# CM_CORE__CORE register map
Vendor: Texas Instruments
Peripheral module from a debugger description file (folder am572x).
Registers are 32-bit, read-only, reset 0x30001 unless marked. A register's access mark holds for its fields unless they carry their own. Offsets are as the file gives them; lines under a group give offsets from that group; [hi:lo] are bit positions; {n}, {i} and the like mark numbered series; 'fields as' and 'values as' point back to an identical list; <NAME> marks a mode.

## CM_CORE__CORE
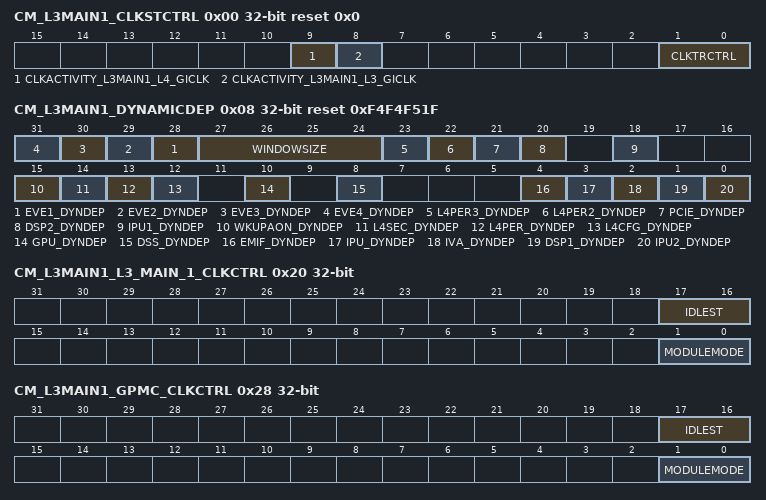
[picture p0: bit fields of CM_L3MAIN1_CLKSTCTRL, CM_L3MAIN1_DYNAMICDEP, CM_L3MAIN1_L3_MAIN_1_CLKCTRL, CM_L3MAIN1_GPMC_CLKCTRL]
0x00 CM_L3MAIN1_CLKSTCTRL access per field reset 0x0 — This register enables the domain power state transition. It controls the HW supervised domain power state transition between ON-ACTIVE and ON-INACTIVE states. It also hold one status bit per clock input of the domain.
  [9] CLKACTIVITY_L3MAIN1_L4_GICLK ro — This field indicates the state of the L3MAIN1_L4_GICLK clock in the domain. [warm reset insensitive]
    0=INACT (Corresponding clock is definitely gated); 1=ACT (Corresponding clock is running or gating/ungating transition is on-going)
  [8] CLKACTIVITY_L3MAIN1_L3_GICLK ro — This field indicates the state of the L3MAIN1_L3_GICLK clock in the domain. [warm reset insensitive]
    values as CLKACTIVITY_L3MAIN1_L4_GICLK
  [1:0] CLKTRCTRL rw — Controls the clock state transition of the L3MAIN1 clock domain.
    0=NO_SLEEP (NO_SLEEP: Sleep transition cannot be initiated. Wakeup transition may however occur.); 3=HW_AUTO (HW_AUTO: Automatic transition is enabled. Sleep and wakeup transition are based upon hardware conditions.)
0x08 CM_L3MAIN1_DYNAMICDEP access per field reset 0xF4F4F51F — This register controls the dynamic domain depedencies from L3MAIN1 domain towards 'target' domains. It is relevant only for domain having OCP master port(s).
  [n+27] EVE{n}_DYNDEP ro (n=1..4) — Dynamic dependency towards EVE{n} clock domain
    1=ENABLED (Dependency is enabled)
  [27:24] WINDOWSIZE rw — Size of sliding window used to monitor OCP interface activity for determination of auto-sleep feature. Time unit defined byCM_DYN_DEP_PRESCAL register.
  [23] L4PER3_DYNDEP ro — Dynamic dependency towards L4PER3 clock domain
    1=ENABLED (Dependency is enabled)
  [22] L4PER2_DYNDEP ro — Dynamic dependency towards L4PER2 clock domain
    1=ENABLED (Dependency is enabled)
  [21] PCIE_DYNDEP ro — Dynamic dependency towards PCIE clock domain
    1=ENABLED (Dependency is enabled)
  [20] DSP2_DYNDEP ro — Dynamic dependency towards DSP2 clock domain
    1=ENABLED (Dependency is enabled)
  [18] IPU1_DYNDEP ro — Dynamic dependency towards IPU1 clock domain
    1=ENABLED (Dependency is enabled)
  [15] WKUPAON_DYNDEP ro — Dynamic dependency towards WKUPAON clock domain
    1=ENABLED (Dependency is enabled)
  [14] L4SEC_DYNDEP ro — Dynamic dependency towards L4SEC clock domain
    1=ENABLED (Dependency is enabled)
  [13] L4PER_DYNDEP ro — Dynamic dependency towards L4PER1 clock domain
    1=ENABLED (Dependency is enabled)
  [12] L4CFG_DYNDEP ro — Dynamic dependency towards L4CFG clock domain
    1=ENABLED (Dependency is enabled)
  [10] GPU_DYNDEP ro — Dynamic dependency towards GPU clock domain
    1=ENABLED (Dependency is enabled)
  [8] DSS_DYNDEP ro — Dynamic dependency towards DSS clock domain
    1=ENABLED (Dependency is enabled)
  [4] EMIF_DYNDEP ro — Dynamic dependency towards EMIF clock domain
    1=ENABLED (Dependency is enabled)
  [3] IPU_DYNDEP ro — Dynamic dependency towards IPU clock domain
    1=ENABLED (Dependency is enabled)
  [2] IVA_DYNDEP ro — Dynamic dependency towards IVA clock domain
    1=ENABLED (Dependency is enabled)
  [1] DSP1_DYNDEP ro — Dynamic dependency towards DSP1 clock domain
    1=ENABLED (Dependency is enabled)
  [0] IPU2_DYNDEP ro — Dynamic dependency towards IPU2 clock domain
    1=ENABLED (Dependency is enabled)
0x20 CM_L3MAIN1_L3_MAIN_1_CLKCTRL — This register manages the L3_MAIN_1 clocks.
  [17:16] IDLEST — Module idle status. [warm reset insensitive]
    0=FUNC (Module is fully functional, including OCP); 1=TRANS (Module is performing transition: wakeup, or sleep, or sleep abortion); 2=IDLE (Module is in Idle mode (only OCP part). It is functional if using separate functional clock); 3=DISABLE (Module is disabled and cannot be accessed)
  [1:0] MODULEMODE — Control the way mandatory clocks are managed.
    1=AUTO (Module is managed automatically by HW according to clock domain transition. A clock domain sleep transition put module into idle. A wakeup domain transition put it back into function. If CLKTRCTRL=3, any OCP access to module is always granted. Module clocks may be gated according to the clock domain state.)
0x28 CM_L3MAIN1_GPMC_CLKCTRL access per field — This register manages the GPMC clocks.
  [17:16] IDLEST ro — Module idle status. [warm reset insensitive]
    values as CM_L3MAIN1_L3_MAIN_1_CLKCTRL.IDLEST
  [1:0] MODULEMODE rw — Control the way mandatory clocks are managed.
    0=DISABLED (Module is temporarily disabled by SW. OCP access to module are stalled. Can be used to change timing parameter of GPMC module.); 1=AUTO (Module is managed automatically by HW according to clock domain transition. A clock domain sleep transition put module into idle. A wakeup domain transition put it back into function. If CLKTRCTRL=3, any OCP access to module is always granted. Module clocks may be gated according to the clock domain state.)
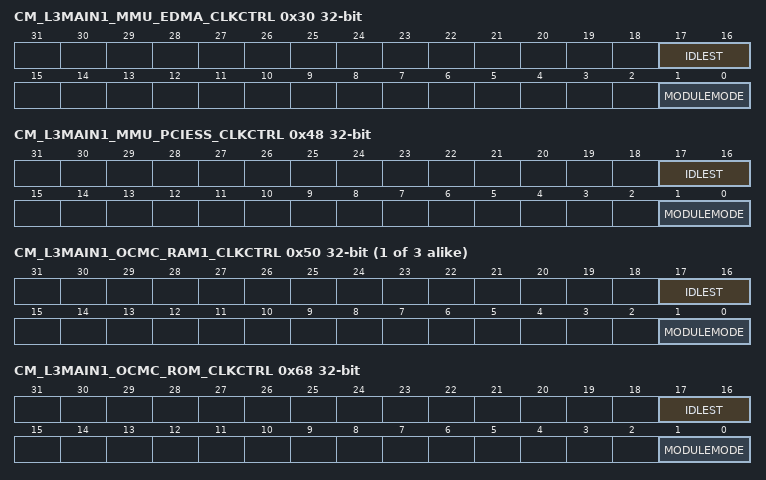
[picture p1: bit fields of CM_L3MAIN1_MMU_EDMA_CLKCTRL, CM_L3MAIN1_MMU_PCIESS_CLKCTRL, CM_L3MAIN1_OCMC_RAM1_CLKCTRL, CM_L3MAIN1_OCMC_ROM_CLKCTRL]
0x30 CM_L3MAIN1_MMU_EDMA_CLKCTRL — This register manages the MMU_L4_EDMA clocks.
  fields as CM_L3MAIN1_L3_MAIN_1_CLKCTRL
0x48 CM_L3MAIN1_MMU_PCIESS_CLKCTRL — This register manages the MMU_L4_PCIESS clocks.
  fields as CM_L3MAIN1_L3_MAIN_1_CLKCTRL
{0x48+8i} CM_L3MAIN1_OCMC_RAM{i}_CLKCTRL (i=1..3) — This register manages the OCMC_RAM{i} clocks.
  fields as CM_L3MAIN1_L3_MAIN_1_CLKCTRL
0x68 CM_L3MAIN1_OCMC_ROM_CLKCTRL — This register manages the OCMC_RAM clocks.
  fields as CM_L3MAIN1_L3_MAIN_1_CLKCTRL
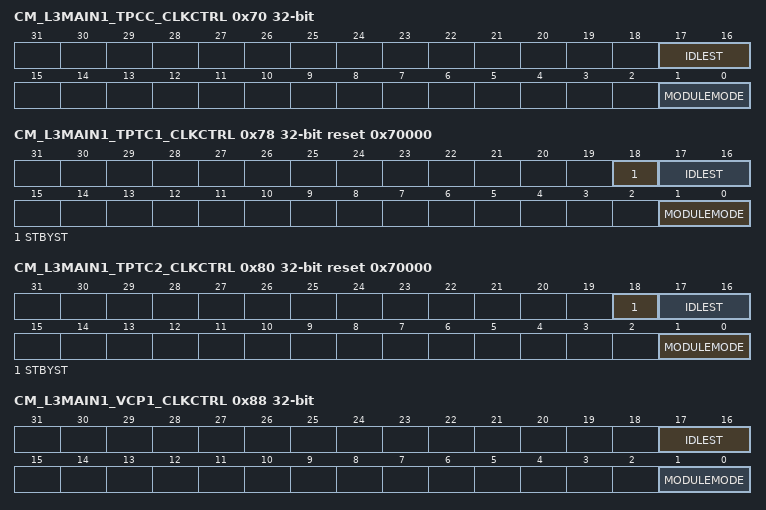
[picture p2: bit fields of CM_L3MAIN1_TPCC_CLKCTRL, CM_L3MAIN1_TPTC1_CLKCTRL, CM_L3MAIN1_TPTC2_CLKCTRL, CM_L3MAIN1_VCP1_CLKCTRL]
0x70 CM_L3MAIN1_TPCC_CLKCTRL — This register manages the TPCC clocks.
  fields as CM_L3MAIN1_L3_MAIN_1_CLKCTRL
0x78 CM_L3MAIN1_TPTC1_CLKCTRL access per field reset 0x70000 — This register manages the TPTC1 clocks.
  [18] STBYST ro — Module standby status. [warm reset insensitive]
    0=FUNC (Module is functional (not in standby)); 1=STANDBY (Module is in standby)
  [17:16] IDLEST ro — Module idle status. [warm reset insensitive]
    values as CM_L3MAIN1_L3_MAIN_1_CLKCTRL.IDLEST
  [1:0] MODULEMODE rw — Control the way mandatory clocks are managed.
    0=DISABLED (Module is disabled by SW. Any OCP access to module results in an error, except if resulting from a module wakeup (asynchronous wakeup).); 1=AUTO (Module is managed automatically by HW according to clock domain transition. A clock domain sleep transition put module into idle. A wakeup domain transition put it back into function. If CLKTRCTRL=3, any OCP access to module is always granted. Module clocks may be gated according to the clock domain state.)
0x80 CM_L3MAIN1_TPTC2_CLKCTRL access per field reset 0x70000 — This register manages the TPTC2 clocks.
  fields as CM_L3MAIN1_TPTC1_CLKCTRL
0x88 CM_L3MAIN1_VCP1_CLKCTRL — This register manages the VCP1 clocks.
  [17:16] IDLEST — Module idle status. [warm reset insensitive]
    0=FUNC (Module is fully functional, including OCP); 1=TRANS (Module is performing transition: wakeup, or sleep, or sleep abortion); 2=DISABLE (Module is in Idle mode (only OCP part). It is functional if using separate functional clock); 3=IDLE (Module is disabled and cannot be accessed)
  [1:0] MODULEMODE — Control the way mandatory clocks are managed.
    values as CM_L3MAIN1_L3_MAIN_1_CLKCTRL.MODULEMODE
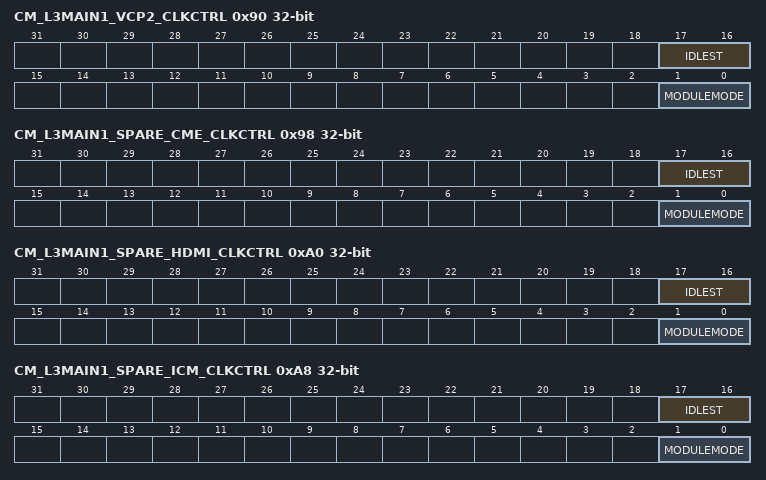
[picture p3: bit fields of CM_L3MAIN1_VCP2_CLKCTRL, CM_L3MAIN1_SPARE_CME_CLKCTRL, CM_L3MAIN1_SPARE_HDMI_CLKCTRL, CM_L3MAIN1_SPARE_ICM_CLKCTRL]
0x90 CM_L3MAIN1_VCP2_CLKCTRL — This register manages the VCP2 clocks.
  fields as CM_L3MAIN1_L3_MAIN_1_CLKCTRL
0x98 CM_L3MAIN1_SPARE_CME_CLKCTRL — This register manages the SPARE_CME clocks.
  fields as CM_L3MAIN1_L3_MAIN_1_CLKCTRL
0xA0 CM_L3MAIN1_SPARE_HDMI_CLKCTRL — This register manages the SPARE_HDMI clocks.
  fields as CM_L3MAIN1_L3_MAIN_1_CLKCTRL
0xA8 CM_L3MAIN1_SPARE_ICM_CLKCTRL — This register manages the SPARE_ICM clocks.
  fields as CM_L3MAIN1_L3_MAIN_1_CLKCTRL
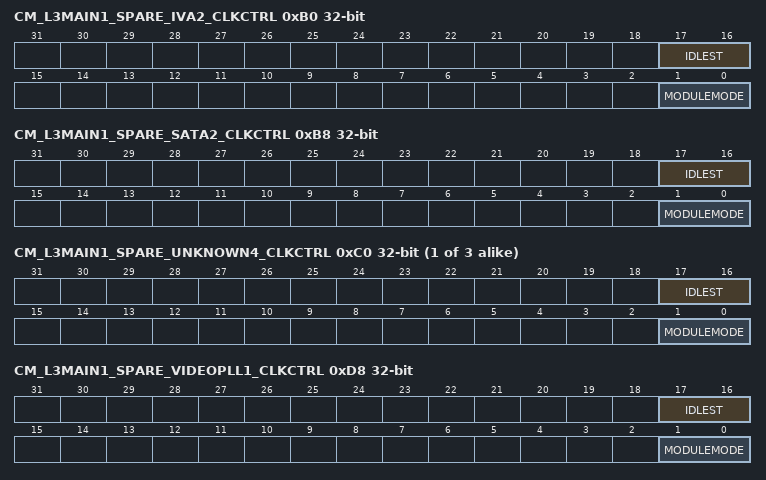
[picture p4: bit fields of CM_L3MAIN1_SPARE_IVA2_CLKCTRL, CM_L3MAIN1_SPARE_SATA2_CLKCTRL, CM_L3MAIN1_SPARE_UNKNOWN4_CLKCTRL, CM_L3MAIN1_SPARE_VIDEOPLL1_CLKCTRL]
0xB0 CM_L3MAIN1_SPARE_IVA2_CLKCTRL — This register manages the SPARE_IVA2 clocks.
  fields as CM_L3MAIN1_L3_MAIN_1_CLKCTRL
0xB8 CM_L3MAIN1_SPARE_SATA2_CLKCTRL — This register manages the SPARE_SATA2 clocks.
  fields as CM_L3MAIN1_L3_MAIN_1_CLKCTRL
{0xA0+8i} CM_L3MAIN1_SPARE_UNKNOWN{i}_CLKCTRL (i=4..6) — This register manages the SPARE_UNKNOWN{i} clocks.
  fields as CM_L3MAIN1_L3_MAIN_1_CLKCTRL
0xD8 CM_L3MAIN1_SPARE_VIDEOPLL1_CLKCTRL — This register manages the SPARE_VIDEOPLL1 clocks.
  fields as CM_L3MAIN1_L3_MAIN_1_CLKCTRL
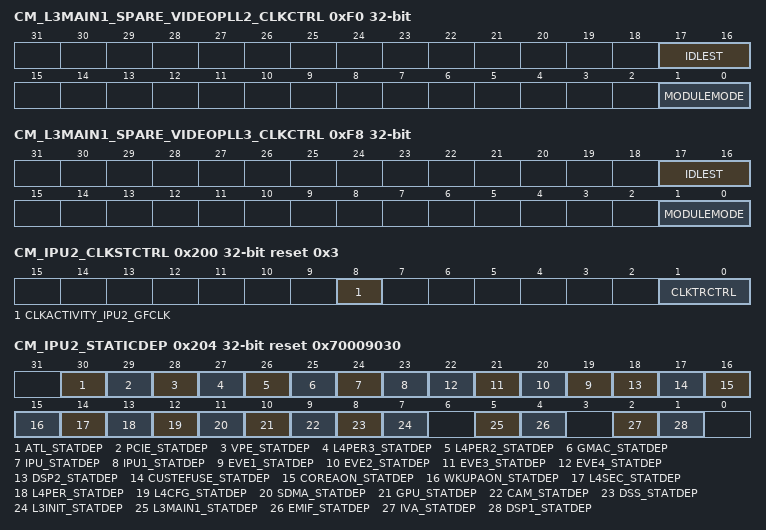
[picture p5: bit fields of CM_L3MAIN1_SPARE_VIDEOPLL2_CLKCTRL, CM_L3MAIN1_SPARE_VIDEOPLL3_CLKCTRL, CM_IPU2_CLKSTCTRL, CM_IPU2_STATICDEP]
0xF0 CM_L3MAIN1_SPARE_VIDEOPLL2_CLKCTRL — This register manages the SPARE_VIDEOPLL2 clocks.
  fields as CM_L3MAIN1_L3_MAIN_1_CLKCTRL
0xF8 CM_L3MAIN1_SPARE_VIDEOPLL3_CLKCTRL — This register manages the SPARE_VIDEOPLL3 clocks.
  fields as CM_L3MAIN1_L3_MAIN_1_CLKCTRL
0x200 CM_IPU2_CLKSTCTRL access per field reset 0x3 — This register enables the domain power state transition. It controls the HW supervised domain power state transition between ON-ACTIVE and ON-INACTIVE states. It also hold one status bit per clock input of the domain.
  [8] CLKACTIVITY_IPU2_GFCLK ro — This field indicates the state of the IPU2_GFCLK clock in the domain. [warm reset insensitive]
    values as CM_L3MAIN1_CLKSTCTRL.CLKACTIVITY_L3MAIN1_L4_GICLK
  [1:0] CLKTRCTRL rw — Controls the clock state transition of the IPU2 clock domain.
    0=NO_SLEEP (NO_SLEEP: Sleep transition cannot be initiated. Wakeup transition may however occur.); 1=SW_SLEEP (SW_SLEEP: Start a software forced sleep transition on the domain.); 2=SW_WKUP (SW_WKUP: Start a software forced wake-up transition on the domain.); 3=HW_AUTO (HW_AUTO: Automatic transition is enabled. Sleep and wakeup transition are based upon hardware conditions.)
0x204 CM_IPU2_STATICDEP access per field reset 0x70009030 — This register controls the static domain depedencies from IPU domain towards 'target' domains. It is relevant only for domain having system initiator(s).
  [30] ATL_STATDEP ro — Static dependency towards ATL clock domain
    0=Dependency_is_disabled; 1=Dependency_is_enabled
  [29] PCIE_STATDEP rw — Static dependency towards PCIE clock domain
    0=DISABLED (Dependency is disabled); 1=ENABLED (Dependency is enabled)
  [28] VPE_STATDEP rw — Static dependency towards VPE clock domain
    values as PCIE_STATDEP
  [27] L4PER3_STATDEP rw — Static dependency towards L4PER3 clock domain
    values as PCIE_STATDEP
  [26] L4PER2_STATDEP rw — Static dependency towards L4PER2 clock domain
    values as PCIE_STATDEP
  [25] GMAC_STATDEP rw — Static dependency towards GMAC clock domain
    values as PCIE_STATDEP
  [24] IPU_STATDEP rw — Static dependency towards IPU clock domain
    values as PCIE_STATDEP
  [23] IPU1_STATDEP rw — Static dependency towards IPU1 clock domain
    values as PCIE_STATDEP
  [n+18] EVE{n}_STATDEP rw (n=1..4) — Static dependency towards EVE{n} clock domain
    values as PCIE_STATDEP
  [18] DSP2_STATDEP rw — Static dependency towards DSP2 clock domain
    values as PCIE_STATDEP
  [17] CUSTEFUSE_STATDEP ro — Static dependency towards CUSTEFUSE clock domain
    0=DISABLED (Dependency is disabled)
  [16] COREAON_STATDEP ro — Static dependency towards COREAON clock domain
    0=DISABLED (Dependency is disabled)
  [15] WKUPAON_STATDEP rw — Static dependency towards WKUPAON clock domain
    values as PCIE_STATDEP
  [14] L4SEC_STATDEP rw — Static dependency towards L4SEC clock domain
    values as PCIE_STATDEP
  [13] L4PER_STATDEP rw — Static dependency towards L4PER1 clock domain
    values as PCIE_STATDEP
  [12] L4CFG_STATDEP rw — Static dependency towards L4CFG clock domain
    values as PCIE_STATDEP
  [11] SDMA_STATDEP ro — Static dependency towards DMA clock domain
    0=DISABLED (Dependency is disabled)
  [10] GPU_STATDEP rw — Static dependency towards GPU clock domain
    values as PCIE_STATDEP
  [9] CAM_STATDEP ro — Static dependency towards CAM clock domain
    0=DISABLED (Dependency is disabled)
  [8] DSS_STATDEP rw — Static dependency towards DSS clock domain
    values as PCIE_STATDEP
  [7] L3INIT_STATDEP rw — Static dependency towards L3INIT clock domain
    values as PCIE_STATDEP
  [5] L3MAIN1_STATDEP rw — Static dependency towards L3MAIN1 clock domain
    values as PCIE_STATDEP
  [4] EMIF_STATDEP rw — Static dependency towards EMIF clock domain
    values as PCIE_STATDEP
  [2] IVA_STATDEP rw — Static dependency towards IVA clock domain
    values as PCIE_STATDEP
  [1] DSP1_STATDEP rw — Static dependency towards DSP clock domain
    values as PCIE_STATDEP
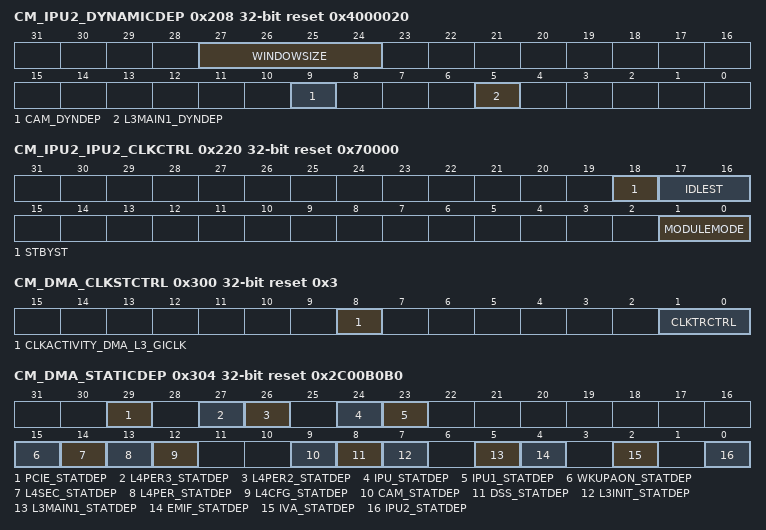
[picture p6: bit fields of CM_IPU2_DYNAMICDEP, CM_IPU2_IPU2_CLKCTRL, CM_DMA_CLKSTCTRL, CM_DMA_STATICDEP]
0x208 CM_IPU2_DYNAMICDEP access per field reset 0x4000020 — This register controls the dynamic domain depedencies from IPU domain towards 'target' domains. It is relevant only for domain having OCP master port(s).
  [27:24] WINDOWSIZE rw — Size of sliding window used to monitor OCP interface activity for determination of auto-sleep feature. Time unit defined byCM_DYN_DEP_PRESCAL register.
  [9] CAM_DYNDEP ro — Dynamic dependency towards CAM clock domain
    0=DISABLED (Dependency is disabled)
  [5] L3MAIN1_DYNDEP ro — Dynamic dependency towards L3MAIN1 clock domain
    1=ENABLED (Dependency is enabled)
0x220 CM_IPU2_IPU2_CLKCTRL access per field reset 0x70000 — This register manages the IPU2 clocks.
  fields as CM_L3MAIN1_TPTC1_CLKCTRL
0x300 CM_DMA_CLKSTCTRL access per field reset 0x3 — This register enables the domain power state transition. It controls the HW supervised domain power state transition between ON-ACTIVE and ON-INACTIVE states. It also hold one status bit per clock input of the domain.
  [8] CLKACTIVITY_DMA_L3_GICLK ro — This field indicates the state of the DMA_L3_GICLK clock in the domain. [warm reset insensitive]
    values as CM_L3MAIN1_CLKSTCTRL.CLKACTIVITY_L3MAIN1_L4_GICLK
  [1:0] CLKTRCTRL rw — Controls the clock state transition of the DMA clock domain.
    0=NO_SLEEP (NO_SLEEP: Sleep transition cannot be initiated. Wakeup transition may however occur.); 2=SW_WKUP (SW_WKUP: Start a software forced wake-up transition on the domain.); 3=HW_AUTO (HW_AUTO: Automatic transition is enabled. Sleep and wakeup transition are based upon hardware conditions.)
0x304 CM_DMA_STATICDEP access per field reset 0x2C00B0B0 — This register controls the static domain depedencies from DMA domain towards 'target' domains. It is relevant only for domain having system initiator(s).
  [29] PCIE_STATDEP rw — Static dependency towards PCIE clock domain
    values as CM_IPU2_STATICDEP.PCIE_STATDEP
  [27] L4PER3_STATDEP rw — Static dependency towards L4PER3 clock domain
    values as CM_IPU2_STATICDEP.PCIE_STATDEP
  [26] L4PER2_STATDEP rw — Static dependency towards L4PER2 clock domain
    values as CM_IPU2_STATICDEP.PCIE_STATDEP
  [24] IPU_STATDEP rw — Static dependency towards IPU clock domain
    values as CM_IPU2_STATICDEP.PCIE_STATDEP
  [23] IPU1_STATDEP rw — Static dependency towards IPU1 clock domain
    values as CM_IPU2_STATICDEP.PCIE_STATDEP
  [15] WKUPAON_STATDEP rw — Static dependency towards WKUPAON clock domain
    values as CM_IPU2_STATICDEP.PCIE_STATDEP
  [14] L4SEC_STATDEP rw — Static dependency towards L4SEC clock domain
    values as CM_IPU2_STATICDEP.PCIE_STATDEP
  [13] L4PER_STATDEP rw — Static dependency towards L4PER1 clock domain
    values as CM_IPU2_STATICDEP.PCIE_STATDEP
  [12] L4CFG_STATDEP rw — Static dependency towards L4CFG clock domain
    values as CM_IPU2_STATICDEP.PCIE_STATDEP
  [9] CAM_STATDEP ro — Static dependency towards CAM clock domain
    0=DISABLED (Dependency is disabled)
  [8] DSS_STATDEP rw — Static dependency towards DSS clock domain
    values as CM_IPU2_STATICDEP.PCIE_STATDEP
  [7] L3INIT_STATDEP rw — Static dependency towards L3INIT clock domain
    values as CM_IPU2_STATICDEP.PCIE_STATDEP
  [5] L3MAIN1_STATDEP ro — Static dependency towards L3MAIN1 clock domain
    1=ENABLED (Dependency is enabled)
  [4] EMIF_STATDEP rw — Static dependency towards EMIF clock domain
    values as CM_IPU2_STATICDEP.PCIE_STATDEP
  [2] IVA_STATDEP rw — Static dependency towards IVA clock domain
    values as CM_IPU2_STATICDEP.PCIE_STATDEP
  [0] IPU2_STATDEP rw — Static dependency towards IPU2 clock domain
    values as CM_IPU2_STATICDEP.PCIE_STATDEP
0x308 CM_DMA_DYNAMICDEP reset 0x0 — This register controls the dynamic domain depedencies from SDMA domain towards 'target' domains. It is relevant only for domain having OCP master port(s).
  [5] L3MAIN1_DYNDEP — Dynamic dependency towards L3MAIN1 clock domain
    0=DISABLED (Dependency is disabled)
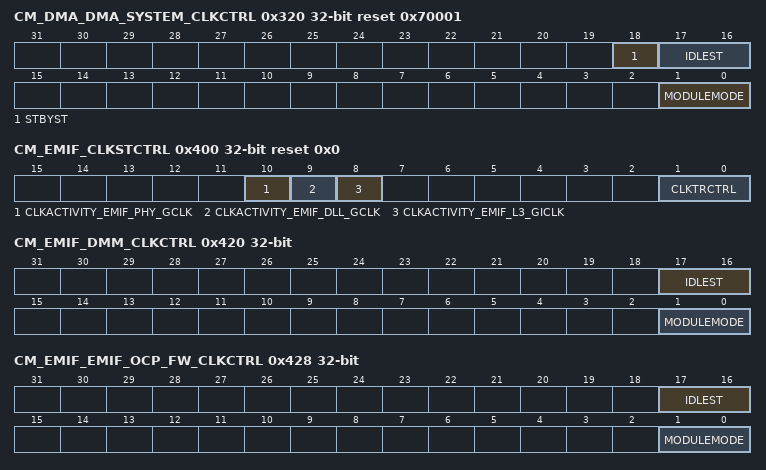
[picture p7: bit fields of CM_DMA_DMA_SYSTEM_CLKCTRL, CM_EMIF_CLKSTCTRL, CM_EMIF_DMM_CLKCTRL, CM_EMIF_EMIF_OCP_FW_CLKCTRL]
0x320 CM_DMA_DMA_SYSTEM_CLKCTRL reset 0x70001 — This register manages the DMA_SYSTEM clocks.
  [18] STBYST — Module standby status. [warm reset insensitive]
    values as CM_L3MAIN1_TPTC1_CLKCTRL.STBYST
  [17:16] IDLEST — Module idle status. [warm reset insensitive]
    values as CM_L3MAIN1_L3_MAIN_1_CLKCTRL.IDLEST
  [1:0] MODULEMODE — Control the way mandatory clocks are managed.
    values as CM_L3MAIN1_L3_MAIN_1_CLKCTRL.MODULEMODE
0x400 CM_EMIF_CLKSTCTRL access per field reset 0x0 — This register enables the domain power state transition. It controls the HW supervised domain power state transition between ON-ACTIVE and ON-INACTIVE states. It also hold one status bit per clock input of the domain.
  [10] CLKACTIVITY_EMIF_PHY_GCLK ro — This field indicates the state of the EMIF_PHY_GCLK clock in the domain. [warm reset insensitive]
    values as CM_L3MAIN1_CLKSTCTRL.CLKACTIVITY_L3MAIN1_L4_GICLK
  [9] CLKACTIVITY_EMIF_DLL_GCLK ro — This field indicates the state of the DLL_GCLK clock in the domain. [warm reset insensitive]
    values as CM_L3MAIN1_CLKSTCTRL.CLKACTIVITY_L3MAIN1_L4_GICLK
  [8] CLKACTIVITY_EMIF_L3_GICLK ro — This field indicates the state of the EMIF_L3_GICLK clock in the domain. [warm reset insensitive]
    values as CM_L3MAIN1_CLKSTCTRL.CLKACTIVITY_L3MAIN1_L4_GICLK
  [1:0] CLKTRCTRL rw — Controls the clock state transition of the EMIF clock domain.
    values as CM_DMA_CLKSTCTRL.CLKTRCTRL
0x420 CM_EMIF_DMM_CLKCTRL — This register manages the DMM clocks.
  fields as CM_L3MAIN1_L3_MAIN_1_CLKCTRL
0x428 CM_EMIF_EMIF_OCP_FW_CLKCTRL — This register manages the EMIF_OCP_FW clocks.
  fields as CM_L3MAIN1_L3_MAIN_1_CLKCTRL
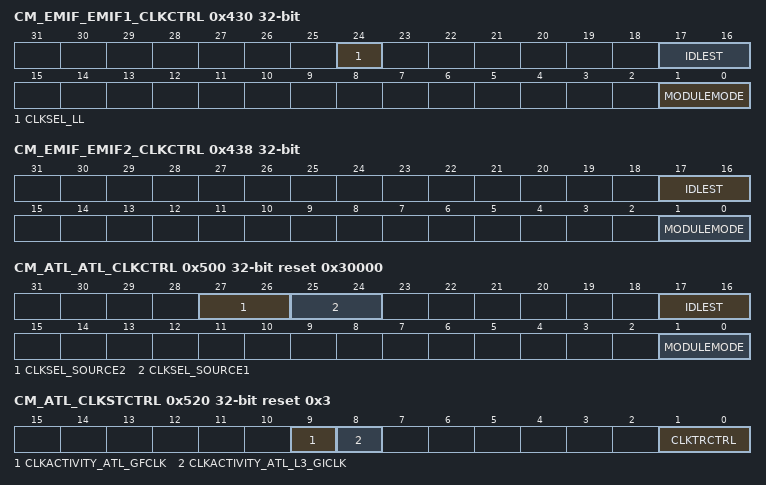
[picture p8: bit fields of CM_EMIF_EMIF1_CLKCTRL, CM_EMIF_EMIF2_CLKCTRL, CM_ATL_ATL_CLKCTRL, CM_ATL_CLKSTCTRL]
0x430 CM_EMIF_EMIF1_CLKCTRL access per field — This register manages the EMIF1 clocks.
  [24] CLKSEL_LL ro — Source of EMIF1 External Low Latency interface clock EMIF_LL_GCLK Value is provided by LLI_C2C_SELECT input pin
    0=EMIF_LL_GCLK_is_same_as_C2C_clock; 1=EMIF_LL_GCLK_is_same_as_LLI_clock
  [17:16] IDLEST ro — Module idle status. [warm reset insensitive]
    values as CM_L3MAIN1_L3_MAIN_1_CLKCTRL.IDLEST
  [1:0] MODULEMODE rw — Control the way mandatory clocks are managed.
    0=DISABLED (Module is temporarily disabled by SW. OCP access to module are stalled. Can be used to change timing parameter of EMIF_1 module.); 1=AUTO (Module is managed automatically by HW according to clock domain transition. A clock domain sleep transition put module into idle. A wakeup domain transition put it back into function. If CLKTRCTRL=3, any OCP access to module is always granted. Module clocks may be gated according to the clock domain state.)
0x438 CM_EMIF_EMIF2_CLKCTRL access per field — This register manages the EMIF2 clocks.
  [17:16] IDLEST ro — Module idle status. [warm reset insensitive]
    values as CM_L3MAIN1_L3_MAIN_1_CLKCTRL.IDLEST
  [1:0] MODULEMODE rw — Control the way mandatory clocks are managed.
    0=DISABLED (Module is temporarily disabled by SW. OCP access to module are stalled. Can be used to change timing parameter of EMIF_2 module.); 1=AUTO (Module is managed automatically by HW according to clock domain transition. A clock domain sleep transition put module into idle. A wakeup domain transition put it back into function. If CLKTRCTRL=3, any OCP access to module is always granted. Module clocks may be gated according to the clock domain state.)
0x440 CM_EMIF_EMIF_DLL_CLKCTRL access per field reset 0x0 — This register manages the DLL clock.
  [8] OPTFCLKEN_DLL_CLK rw — Optional functional clock control.
    0=FCLK_DIS (Optional functional clock is disabled. DLL_CLK can be gated when EMIF domain performs sleep transition); 1=FCLK_EN (Optional functional clock is enabled. DLL_CLK is garantied to not be gated if already running.)
0x500 CM_ATL_ATL_CLKCTRL access per field reset 0x30000 — This register manages the ATL clocks.
  [27:26] CLKSEL_SOURCE2 rw — Selects source for ATL clock
    0=SEL_L3_ICLK (Selects L3_ICLK); 1=SEL_PER_ABE_X1_CLK (Selects ABE_GICLK); 2=RESERVED (Selects DPLL_CLK from SOURCE1); 3=SEL_DPLL_CLK (RESERVED)
  [25:24] CLKSEL_SOURCE1 rw — Selects source for ATL clock
    0=SEL_FUNC_32K_CLK (Selects FUNC_32K_CLK); 1=SEL_VIDEO1_CLK (Selects VIDEO1_CLK); 2=SEL_HDMI_CLK (Selects VIDEO2_CLK); 3=SEL_VIDEO2_CLK (Selects HDMI_CLK)
  [17:16] IDLEST ro — Module idle status. [warm reset insensitive]
    values as CM_L3MAIN1_VCP1_CLKCTRL.IDLEST
  [1:0] MODULEMODE rw — Control the way mandatory clocks are managed.
    0=DISABLED (Module is disabled by SW. Any OCP access to module results in an error, except if resulting from a module wakeup (asynchronous wakeup).); 2=RESERVED (Module is explicitly enabled. Interface clock (if not used for functions) may be gated according to the clock domain state. Functional clocks are guaranteed to stay present. As long as in this configuration, power domain sleep transition cannot happen.); 3=ENABLE (Reserved)
0x520 CM_ATL_CLKSTCTRL access per field reset 0x3 — This register enables the domain power state transition. It controls the HW supervised domain power state transition between ON-ACTIVE and ON-INACTIVE states. It also hold one status bit per clock input of the domain.
  [9] CLKACTIVITY_ATL_GFCLK ro — This field indicates the state of the ATL_GFCLK clock in the domain. [warm reset insensitive]
    values as CM_L3MAIN1_CLKSTCTRL.CLKACTIVITY_L3MAIN1_L4_GICLK
  [8] CLKACTIVITY_ATL_L3_GICLK ro — This field indicates the state of the ATL_L3_GICLK clock in the domain. [warm reset insensitive]
    values as CM_L3MAIN1_CLKSTCTRL.CLKACTIVITY_L3MAIN1_L4_GICLK
  [1:0] CLKTRCTRL rw — Controls the clock state transition of the ATL clock domain.
    0=NO_SLEEP (NO_SLEEP: Sleep transition cannot be initiated. Wakeup transition may however occur.); 2=HW_AUTO (SW_WKUP: Start a software forced wake-up transition on the domain.); 3=SW_WKUP (HW_AUTO: Automatic transition is enabled. Sleep and wakeup transition are based upon hardware conditions.)
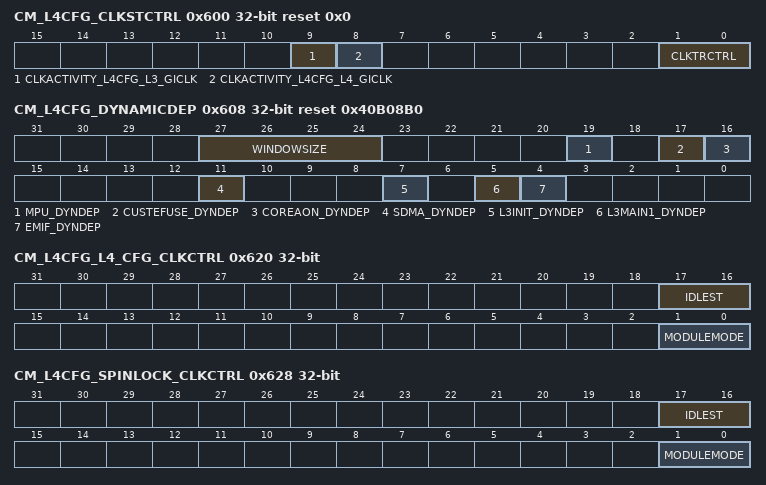
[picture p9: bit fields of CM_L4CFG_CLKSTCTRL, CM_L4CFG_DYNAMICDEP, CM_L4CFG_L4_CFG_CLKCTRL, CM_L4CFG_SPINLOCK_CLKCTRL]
0x600 CM_L4CFG_CLKSTCTRL access per field reset 0x0 — This register enables the domain power state transition. It controls the HW supervised domain power state transition between ON-ACTIVE and ON-INACTIVE states. It also hold one status bit per clock input of the domain.
  [9] CLKACTIVITY_L4CFG_L3_GICLK ro — This field indicates the state of the L4CFG_L3_GICLK clock in the domain. [warm reset insensitive]
    values as CM_L3MAIN1_CLKSTCTRL.CLKACTIVITY_L3MAIN1_L4_GICLK
  [8] CLKACTIVITY_L4CFG_L4_GICLK ro — This field indicates the state of the L4CFG_L4_GICLK clock in the domain. [warm reset insensitive]
    values as CM_L3MAIN1_CLKSTCTRL.CLKACTIVITY_L3MAIN1_L4_GICLK
  [1:0] CLKTRCTRL rw — Controls the clock state transition of the L4CFG clock domain.
    values as CM_L3MAIN1_CLKSTCTRL.CLKTRCTRL
0x608 CM_L4CFG_DYNAMICDEP access per field reset 0x40B08B0 — This register controls the dynamic domain depedencies from L4CFG domain towards 'target' domains. It is relevant only for domain having OCP master port(s).
  [27:24] WINDOWSIZE rw — Size of sliding window used to monitor OCP interface activity for determination of auto-sleep feature. Time unit defined byCM_DYN_DEP_PRESCAL register.
  [19] MPU_DYNDEP ro — Dynamic dependency towards MPU clock domain
    1=ENABLED (Dependency is enabled)
  [17] CUSTEFUSE_DYNDEP ro — Dynamic dependency towards CUSTEFUSE clock domain
    1=ENABLED (Dependency is enabled)
  [16] COREAON_DYNDEP ro — Dynamic dependency towards COREAON clock domain
    1=ENABLED (Dependency is enabled)
  [11] SDMA_DYNDEP ro — Dynamic dependency towards DMA clock domain
    1=ENABLED (Dependency is enabled)
  [7] L3INIT_DYNDEP ro — Dynamic dependency towards L3INIT clock domain
    1=ENABLED (Dependency is enabled)
  [5] L3MAIN1_DYNDEP ro — Dynamic dependency towards L3MAIN1 clock domain
    1=ENABLED (Dependency is enabled)
  [4] EMIF_DYNDEP ro — Dynamic dependency towards EMIF clock domain
    1=ENABLED (Dependency is enabled)
0x620 CM_L4CFG_L4_CFG_CLKCTRL — This register manages the L4_CFG clocks.
  fields as CM_L3MAIN1_L3_MAIN_1_CLKCTRL
0x628 CM_L4CFG_SPINLOCK_CLKCTRL — This register manages the SPINLOCK clocks.
  fields as CM_L3MAIN1_L3_MAIN_1_CLKCTRL
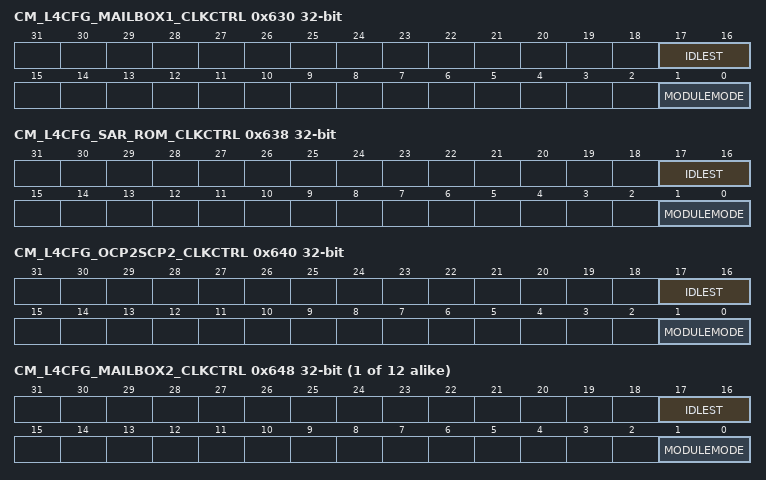
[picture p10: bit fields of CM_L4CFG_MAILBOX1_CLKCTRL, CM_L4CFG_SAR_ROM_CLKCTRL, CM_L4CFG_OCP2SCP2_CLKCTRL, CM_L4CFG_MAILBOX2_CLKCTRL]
0x630 CM_L4CFG_MAILBOX1_CLKCTRL — This register manages the MAILBOX1 clocks.
  fields as CM_L3MAIN1_L3_MAIN_1_CLKCTRL
0x638 CM_L4CFG_SAR_ROM_CLKCTRL — This register manages the SAR_ROM clocks. NOTE: This register is NOT supported on this device.
  fields as CM_L3MAIN1_L3_MAIN_1_CLKCTRL
0x640 CM_L4CFG_OCP2SCP2_CLKCTRL — This register manages the OCP2SCP2 clocks and the optional clock of USB PHY.
  fields as CM_L3MAIN1_L3_MAIN_1_CLKCTRL
{0x638+8i} CM_L4CFG_MAILBOX{i}_CLKCTRL (i=2..13) — This register manages the MAILBOX{i} clocks.
  fields as CM_L3MAIN1_L3_MAIN_1_CLKCTRL
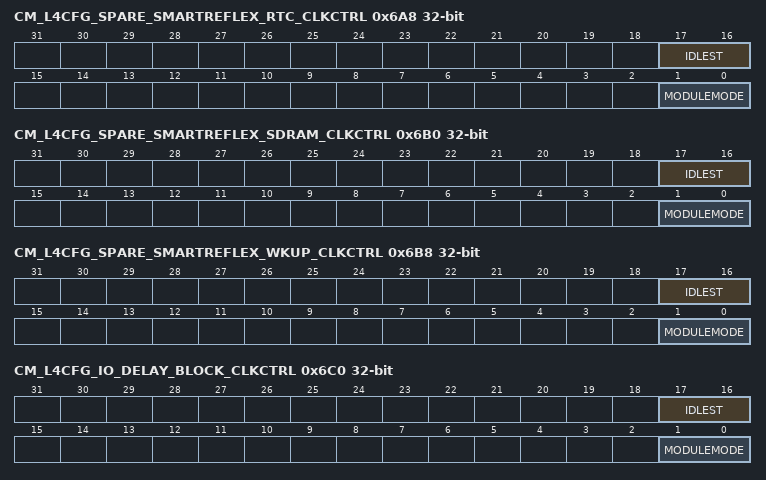
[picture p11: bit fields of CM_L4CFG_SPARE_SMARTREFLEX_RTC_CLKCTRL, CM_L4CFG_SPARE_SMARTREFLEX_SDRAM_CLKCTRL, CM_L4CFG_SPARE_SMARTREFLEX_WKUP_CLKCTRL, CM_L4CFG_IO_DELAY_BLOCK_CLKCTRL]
0x6A8 CM_L4CFG_SPARE_SMARTREFLEX_RTC_CLKCTRL — This register manages the SPARE_SMARTREFLEX_RTC clocks.
  fields as CM_L3MAIN1_L3_MAIN_1_CLKCTRL
0x6B0 CM_L4CFG_SPARE_SMARTREFLEX_SDRAM_CLKCTRL — This register manages the SPARE_SMARTREFLEX_SDRAM clocks.
  fields as CM_L3MAIN1_L3_MAIN_1_CLKCTRL
0x6B8 CM_L4CFG_SPARE_SMARTREFLEX_WKUP_CLKCTRL — This register manages the SPARE_SMARTREFLEX_WKUP clocks.
  fields as CM_L3MAIN1_L3_MAIN_1_CLKCTRL
0x6C0 CM_L4CFG_IO_DELAY_BLOCK_CLKCTRL — This register manages the IO_DELAY_BLOCK clocks.
  fields as CM_L3MAIN1_L3_MAIN_1_CLKCTRL
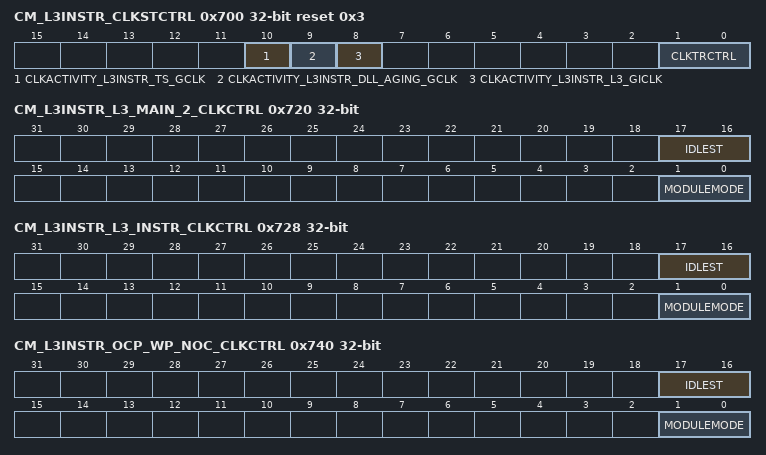
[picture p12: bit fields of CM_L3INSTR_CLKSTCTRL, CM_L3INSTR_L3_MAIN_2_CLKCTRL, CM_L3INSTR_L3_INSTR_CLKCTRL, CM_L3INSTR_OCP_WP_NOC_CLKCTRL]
0x700 CM_L3INSTR_CLKSTCTRL reset 0x3 — This register enables the domain power state transition. It controls the HW supervised domain power state transition between ON-ACTIVE and ON-INACTIVE states. It also hold one status bit per clock input of the domain.
  [10] CLKACTIVITY_L3INSTR_TS_GCLK — This field indicates the state of the L3INSTR_TS_GCLK clock in the domain. [warm reset insensitive]
    values as CM_L3MAIN1_CLKSTCTRL.CLKACTIVITY_L3MAIN1_L4_GICLK
  [9] CLKACTIVITY_L3INSTR_DLL_AGING_GCLK — This field indicates the state of the L3INSTR_DLL_AGING_GCLK clock in the domain. [warm reset insensitive]
    values as CM_L3MAIN1_CLKSTCTRL.CLKACTIVITY_L3MAIN1_L4_GICLK
  [8] CLKACTIVITY_L3INSTR_L3_GICLK — This field indicates the state of the L3INSTR_L3_GICLK clock in the domain. [warm reset insensitive]
    values as CM_L3MAIN1_CLKSTCTRL.CLKACTIVITY_L3MAIN1_L4_GICLK
  [1:0] CLKTRCTRL — Controls the clock state transition of the L3INSTR clock domain.
    3=HW_AUTO (HW_AUTO: Automatic transition is enabled. Sleep and wakeup transition are based upon hardware conditions.)
0x720 CM_L3INSTR_L3_MAIN_2_CLKCTRL access per field — This register manages the L3_MAIN_2 clocks. [warm reset insensitive]
  [17:16] IDLEST ro — Module idle status.
    values as CM_L3MAIN1_L3_MAIN_1_CLKCTRL.IDLEST
  [1:0] MODULEMODE rw — Control the way mandatory clocks are managed.
    values as CM_L3MAIN1_TPTC1_CLKCTRL.MODULEMODE
0x728 CM_L3INSTR_L3_INSTR_CLKCTRL access per field — This register manages the L3 INSTRUMENTATION clocks. [warm reset insensitive]
  fields as CM_L3INSTR_L3_MAIN_2_CLKCTRL
0x740 CM_L3INSTR_OCP_WP_NOC_CLKCTRL access per field — This register manages the OCP_WP_NOC clocks. [warm reset insensitive]
  fields as CM_L3INSTR_L3_MAIN_2_CLKCTRL
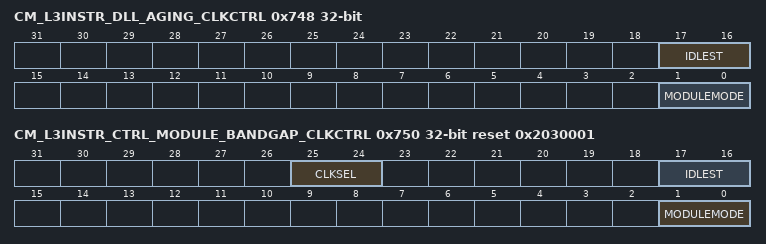
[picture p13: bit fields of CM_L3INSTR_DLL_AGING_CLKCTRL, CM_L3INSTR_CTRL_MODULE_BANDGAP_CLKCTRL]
0x748 CM_L3INSTR_DLL_AGING_CLKCTRL — This register manages the DLL_AGING clocks.
  fields as CM_L3MAIN1_L3_MAIN_1_CLKCTRL
0x750 CM_L3INSTR_CTRL_MODULE_BANDGAP_CLKCTRL access per field reset 0x2030001 — This register manages the CTRL_MODULE_BANDGAP clock.
  [25:24] CLKSEL rw — Selects the divider value for generating the Thermal Sensor clock from WKUPAON_ICLK source. The divider has to be selected so as to guarantee a frequency between 1MHz and 2MHz.
    0=DIV8 (Divide by 8); 1=DIV16 (Divide by 16); 2=DIV32 (Divide by 32)
  [17:16] IDLEST ro — Module idle status. [warm reset insensitive]
    values as CM_L3MAIN1_L3_MAIN_1_CLKCTRL.IDLEST
  [1:0] MODULEMODE ro — Control the way mandatory clocks are managed.
    values as CM_L3MAIN1_L3_MAIN_1_CLKCTRL.MODULEMODE
